# ATSAMA5D27 register map
Vendor: Microchip Technology Inc.; File version: 1.0
CPU: CA5 r0p1, little endian, no MPU, no FPU, 4 interrupt priority bits
Address unit: 32 bits
Registers are 32-bit, read-write, reset 0x0 unless marked. A register's access mark holds for its fields unless they carry their own. Offsets are from the block's base; [hi:lo] are bit positions; {n}, {i} and the like mark numbered series; 'fields as' and 'values as' point back to an identical list.

## SPI0 — Serial Peripheral Interface
Base 0xF8000000
Same registers: SPI1 0xFC000000
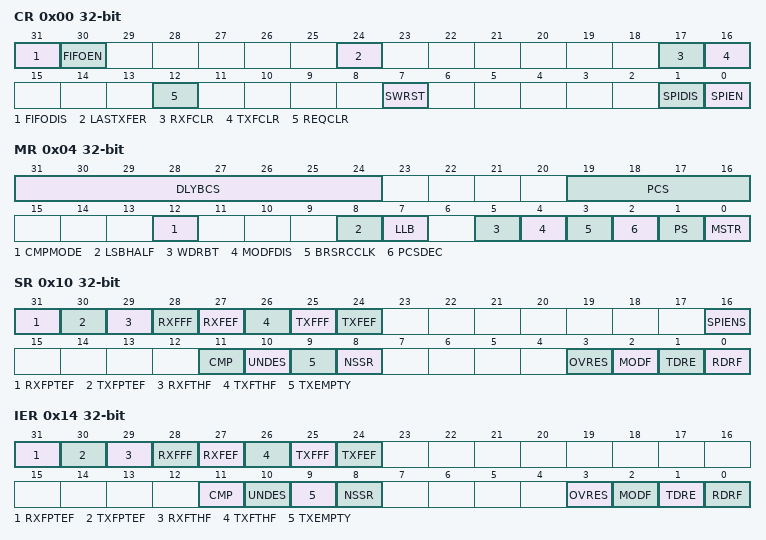
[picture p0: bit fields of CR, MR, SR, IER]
0x00 CR wo — Control Register
  [31] FIFODIS rw — FIFO Disable
  [30] FIFOEN rw — FIFO Enable
  [24] LASTXFER rw — Last Transfer
  [17] RXFCLR rw — Receive FIFO Clear
  [16] TXFCLR rw — Transmit FIFO Clear
  [12] REQCLR rw — Request to Clear the Comparison Trigger
  [7] SWRST rw — SPI Software Reset
  [1] SPIDIS rw — SPI Disable
  [0] SPIEN rw — SPI Enable
0x04 MR — Mode Register
  [31:24] DLYBCS — Delay Between Chip Selects
  [19:16] PCS — Peripheral Chip Select
    7=NPCS3 (NPCS3 as Chip Select); 11=NPCS2 (NPCS2 as Chip Select); 13=NPCS1 (NPCS1 as Chip Select); 14=NPCS0 (NPCS0 as Chip Select)
  [12] CMPMODE — Comparison Mode
    0=FLAG_ONLY (Any character is received and comparison function drives CMP flag.); 1=START_CONDITION (Comparison condition must be met to start reception of all incoming characters until REQCLR is set.)
  [8] LSBHALF — LSB Timing Selection
  [7] LLB — Local Loopback Enable
  [5] WDRBT — Wait Data Read Before Transfer
  [4] MODFDIS — Mode Fault Detection
  [3] BRSRCCLK — Bit Rate Source Clock
    0=PERIPH_CLK (The peripheral clock is the source clock for the bit rate generation.); 1=GCLK (PMC GCLK is the source clock for the bit rate generation, thus the bit rate can be independent of the core/peripheral clock.)
  [2] PCSDEC — Chip Select Decode
  [1] PS — Peripheral Select
  [0] MSTR — Master/Slave Mode
    0=SLAVE; 1=MASTER
0x08 RDR ro — Receive Data Register
  [8n+7:8n] RD8_{n} rw (n=0..3) — Receive Data
  [19:16] PCS rw — Peripheral Chip Select
  [31:16] RD16_1 rw — Receive Data
  [15:0] RD rw — Receive Data
  [15:0] RD16_0 rw — Receive Data
0x0C TDR wo — Transmit Data Register
  [24] LASTXFER rw — Last Transfer
  [19:16] PCS rw — Peripheral Chip Select
    values as MR.PCS
  [31:16] TD1 rw — Transmit Data
  [15:0] TD rw — Transmit Data
  [15:0] TD0 rw — Transmit Data
0x10 SR ro — Status Register
  [31] RXFPTEF rw — Receive FIFO Pointer Error Flag
  [30] TXFPTEF rw — Transmit FIFO Pointer Error Flag
  [29] RXFTHF rw — Receive FIFO Threshold Flag
  [28] RXFFF rw — Receive FIFO Full Flag
  [27] RXFEF rw — Receive FIFO Empty Flag
  [26] TXFTHF rw — Transmit FIFO Threshold Flag (cleared on read)
  [25] TXFFF rw — Transmit FIFO Full Flag (cleared on read)
  [24] TXFEF rw — Transmit FIFO Empty Flag (cleared on read)
  [16] SPIENS rw — SPI Enable Status
  [11] CMP rw — Comparison Status (cleared on read)
  [10] UNDES rw — Underrun Error Status (Slave mode only) (cleared on read)
  [9] TXEMPTY rw — Transmission Registers Empty (cleared by writing SPI_TDR)
  [8] NSSR rw — NSS Rising (cleared on read)
  [3] OVRES rw — Overrun Error Status (cleared on read)
  [2] MODF rw — Mode Fault Error (cleared on read)
  [1] TDRE rw — Transmit Data Register Empty (cleared by writing SPI_TDR)
  [0] RDRF rw — Receive Data Register Full (cleared by reading SPI_RDR)
0x14 IER wo — Interrupt Enable Register
  [31] RXFPTEF rw — RXFPTEF Interrupt Enable
  [30] TXFPTEF rw — TXFPTEF Interrupt Enable
  [29] RXFTHF rw — RXFTHF Interrupt Enable
  [28] RXFFF rw — RXFFF Interrupt Enable
  [27] RXFEF rw — RXFEF Interrupt Enable
  [26] TXFTHF rw — TXFTHF Interrupt Enable
  [25] TXFFF rw — TXFFF Interrupt Enable
  [24] TXFEF rw — TXFEF Interrupt Enable
  [11] CMP rw — Comparison Interrupt Enable
  [10] UNDES rw — Underrun Error Interrupt Enable
  [9] TXEMPTY rw — Transmission Registers Empty Enable
  [8] NSSR rw — NSS Rising Interrupt Enable
  [3] OVRES rw — Overrun Error Interrupt Enable
  [2] MODF rw — Mode Fault Error Interrupt Enable
  [1] TDRE rw — SPI Transmit Data Register Empty Interrupt Enable
  [0] RDRF rw — Receive Data Register Full Interrupt Enable
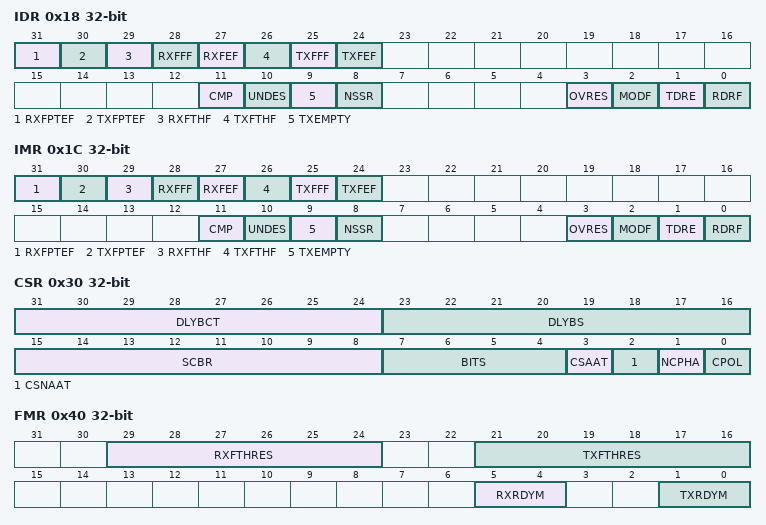
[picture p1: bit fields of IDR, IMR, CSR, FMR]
0x18 IDR wo — Interrupt Disable Register
  [31] RXFPTEF rw — RXFPTEF Interrupt Disable
  [30] TXFPTEF rw — TXFPTEF Interrupt Disable
  [29] RXFTHF rw — RXFTHF Interrupt Disable
  [28] RXFFF rw — RXFFF Interrupt Disable
  [27] RXFEF rw — RXFEF Interrupt Disable
  [26] TXFTHF rw — TXFTHF Interrupt Disable
  [25] TXFFF rw — TXFFF Interrupt Disable
  [24] TXFEF rw — TXFEF Interrupt Disable
  [11] CMP rw — Comparison Interrupt Disable
  [10] UNDES rw — Underrun Error Interrupt Disable
  [9] TXEMPTY rw — Transmission Registers Empty Disable
  [8] NSSR rw — NSS Rising Interrupt Disable
  [3] OVRES rw — Overrun Error Interrupt Disable
  [2] MODF rw — Mode Fault Error Interrupt Disable
  [1] TDRE rw — SPI Transmit Data Register Empty Interrupt Disable
  [0] RDRF rw — Receive Data Register Full Interrupt Disable
0x1C IMR ro — Interrupt Mask Register
  [31] RXFPTEF rw — RXFPTEF Interrupt Mask
  [30] TXFPTEF rw — TXFPTEF Interrupt Mask
  [29] RXFTHF rw — RXFTHF Interrupt Mask
  [28] RXFFF rw — RXFFF Interrupt Mask
  [27] RXFEF rw — RXFEF Interrupt Mask
  [26] TXFTHF rw — TXFTHF Interrupt Mask
  [25] TXFFF rw — TXFFF Interrupt Mask
  [24] TXFEF rw — TXFEF Interrupt Mask
  [11] CMP rw — Comparison Interrupt Mask
  [10] UNDES rw — Underrun Error Interrupt Mask
  [9] TXEMPTY rw — Transmission Registers Empty Mask
  [8] NSSR rw — NSS Rising Interrupt Mask
  [3] OVRES rw — Overrun Error Interrupt Mask
  [2] MODF rw — Mode Fault Error Interrupt Mask
  [1] TDRE rw — SPI Transmit Data Register Empty Interrupt Mask
  [0] RDRF rw — Receive Data Register Full Interrupt Mask
0x30 CSR — Chip Select Register
  [31:24] DLYBCT — Delay Between Consecutive Transfers
  [23:16] DLYBS — Delay Before SPCK
  [15:8] SCBR — Serial Clock Bit Rate
  [7:4] BITS — Bits Per Transfer
    {v}=_{v+8}_BIT ({v+8} bits for transfer) (v=0..8)
  [3] CSAAT — Chip Select Active After Transfer
  [2] CSNAAT — Chip Select Not Active After Transfer (ignored if CSAAT = 1)
  [1] NCPHA — Clock Phase
    0=VALID_TRAILING_EDGE (Data is valid on clock trailing edge (NCPHA=0)); 1=VALID_LEADING_EDGE (Data is valid on clock leading edge (NCPHA=1))
  [0] CPOL — Clock Polarity
    0=IDLE_LOW (Clock is low when inactive (CPOL=0)); 1=IDLE_HIGH (Clock is high when inactive (CPOL=1))
0x40 FMR — FIFO Mode Register
  [29:24] RXFTHRES — Receive FIFO Threshold
  [21:16] TXFTHRES — Transmit FIFO Threshold
  [5:4] RXRDYM — Receive Data Register Full Mode
    0=ONE_DATA (RDRF will be at level '1' when at least one unread data is in the Receive FIFO.); 1=TWO_DATA (RDRF will be at level '1' when at least two unread data are in the Receive FIFO. Cannot be used if SPI_MR.PS =1.); 2=FOUR_DATA (RDRF will be at level '1' when at least four unread data are in the Receive FIFO. Cannot be used when SPI_CSRx.BITS is greater than 0, or if SPI_MR.MSTR =1, or if SPI_MR.PS =1.)
  [1:0] TXRDYM — Transmit Data Register Empty Mode
    0=ONE_DATA (TDRE will be at level '1' when at least one data can be written in the Transmit FIFO.); 1=TWO_DATA (TDRE will be at level '1' when at least two data can be written in the Transmit FIFO. Cannot be used if SPI_MR.PS =1.)
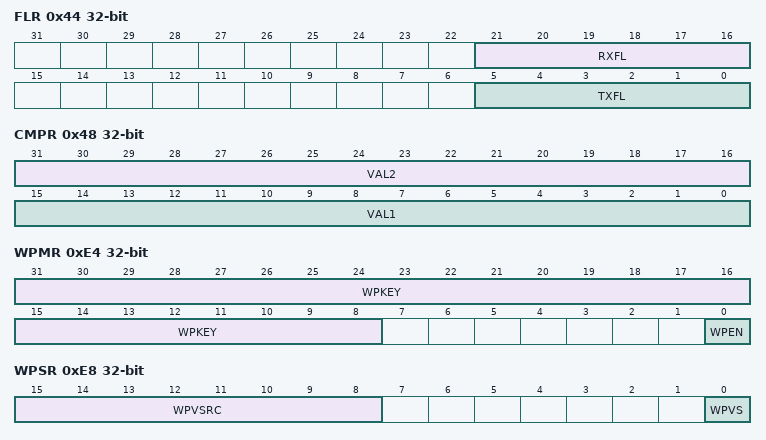
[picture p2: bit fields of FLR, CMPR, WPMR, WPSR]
0x44 FLR ro — FIFO Level Register
  [21:16] RXFL rw — Receive FIFO Level
  [5:0] TXFL rw — Transmit FIFO Level
0x48 CMPR ro — Comparison Register
  [31:16] VAL2 rw — Second Comparison Value for Received Character
  [15:0] VAL1 rw — First Comparison Value for Received Character
0xE4 WPMR — Write Protection Mode Register
  [31:8] WPKEY — Write Protection Key
    0x535049=PASSWD (Writing any other value in this field aborts the write operation of the WPEN bit.Always reads as 0.)
  [0] WPEN — Write Protection Enable
0xE8 WPSR ro — Write Protection Status Register
  [15:8] WPVSRC rw — Write Protection Violation Source
  [0] WPVS rw — Write Protection Violation Status
